# LAN9255ZMX020 register map
Vendor: Microchip
Registers are 32-bit, read-write, reset 0x0 unless marked. A register's access mark holds for its fields unless they carry their own. Addresses are absolute, and some are shared; only a register's first bit layout is shown; [hi:lo] are bit positions; {n}, {i} and the like mark numbered series; 'fields as' and 'values as' point back to an identical list.

## PAC
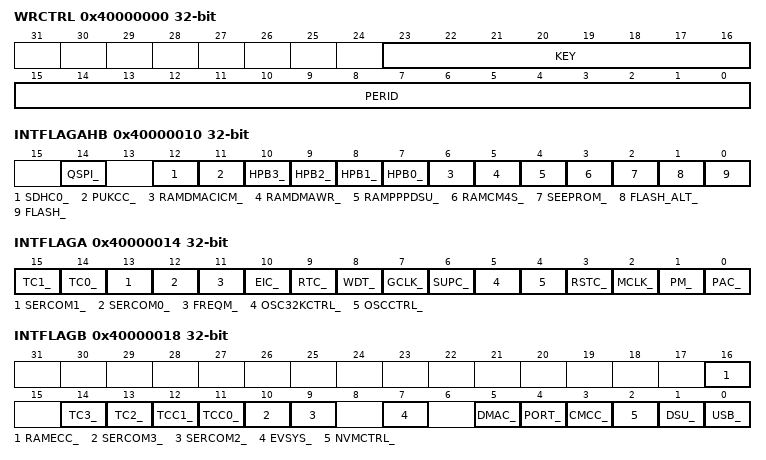
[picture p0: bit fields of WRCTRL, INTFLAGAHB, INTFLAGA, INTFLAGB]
0x40000000 WRCTRL
  [23:16] KEY — Peripheral access control key
    0=OFF (No action); 1=CLR (Clear protection); 2=SET (Set protection); 3=SETLCK (Set and lock protection)
  [15:0] PERID — Peripheral identifier
0x40000004 EVCTRL 8-bit
  [0] ERREO — Peripheral acess error event output
0x40000008 INTENCLR 8-bit
  [0] ERR — Peripheral access error interrupt disable
0x40000009 INTENSET 8-bit
  [0] ERR — Peripheral access error interrupt enable
0x40000010 INTFLAGAHB
  [14] QSPI_, [12] SDHC0_, [11] PUKCC_, [n+7] HPB{n}_ (n=0..3), [6] RAMDMACICM_, [5] RAMDMAWR_, [4] RAMPPPDSU_, [3] RAMCM4S_, [2] SEEPROM_, [1] FLASH_ALT_, [0] FLASH_
0x40000014 INTFLAGA
  [15] TC1_, [14] TC0_, [13] SERCOM1_, [12] SERCOM0_, [11] FREQM_, [10] EIC_, [9] RTC_, [8] WDT_, [7] GCLK_, [6] SUPC_, [5] OSC32KCTRL_, [4] OSCCTRL_, [3] RSTC_, [2] MCLK_, [1] PM_, [0] PAC_
0x40000018 INTFLAGB
  [16] RAMECC_, [14] TC3_, [13] TC2_, [12] TCC1_, [11] TCC0_, [10] SERCOM3_, [9] SERCOM2_, [7] EVSYS_, [5] DMAC_, [4] PORT_, [3] CMCC_, [2] NVMCTRL_, [1] DSU_, [0] USB_
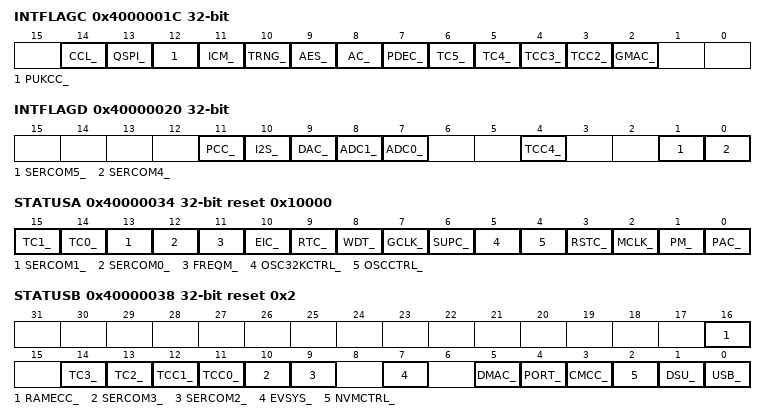
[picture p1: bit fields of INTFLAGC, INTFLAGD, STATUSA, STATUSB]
0x4000001C INTFLAGC
  [14] CCL_, [13] QSPI_, [12] PUKCC_, [11] ICM_, [10] TRNG_, [9] AES_, [8] AC_, [7] PDEC_, [6] TC5_, [5] TC4_, [4] TCC3_, [3] TCC2_, [2] GMAC_
0x40000020 INTFLAGD
  [11] PCC_, [10] I2S_, [9] DAC_, [8] ADC1_, [7] ADC0_, [4] TCC4_, [1] SERCOM5_, [0] SERCOM4_
0x40000034 STATUSA ro reset 0x10000
  [15] TC1_ — TC1 APB Protect Enable
  [14] TC0_ — TC0 APB Protect Enable
  [13] SERCOM1_ — SERCOM1 APB Protect Enable
  [12] SERCOM0_ — SERCOM0 APB Protect Enable
  [11] FREQM_ — FREQM APB Protect Enable
  [10] EIC_ — EIC APB Protect Enable
  [9] RTC_ — RTC APB Protect Enable
  [8] WDT_ — WDT APB Protect Enable
  [7] GCLK_ — GCLK APB Protect Enable
  [6] SUPC_ — SUPC APB Protect Enable
  [5] OSC32KCTRL_ — OSC32KCTRL APB Protect Enable
  [4] OSCCTRL_ — OSCCTRL APB Protect Enable
  [3] RSTC_ — RSTC APB Protect Enable
  [2] MCLK_ — MCLK APB Protect Enable
  [1] PM_ — PM APB Protect Enable
  [0] PAC_ — PAC APB Protect Enable
0x40000038 STATUSB ro reset 0x2
  [16] RAMECC_ — RAMECC APB Protect Enable
  [14] TC3_ — TC3 APB Protect Enable
  [13] TC2_ — TC2 APB Protect Enable
  [12] TCC1_ — TCC1 APB Protect Enable
  [11] TCC0_ — TCC0 APB Protect Enable
  [10] SERCOM3_ — SERCOM3 APB Protect Enable
  [9] SERCOM2_ — SERCOM2 APB Protect Enable
  [7] EVSYS_ — EVSYS APB Protect Enable
  [5] DMAC_ — DMAC APB Protect Enable
  [4] PORT_ — PORT APB Protect Enable
  [3] CMCC_ — CMCC APB Protect Enable
  [2] NVMCTRL_ — NVMCTRL APB Protect Enable
  [1] DSU_ — DSU APB Protect Enable
  [0] USB_ — USB APB Protect Enable
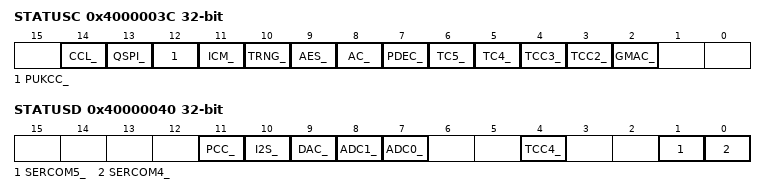
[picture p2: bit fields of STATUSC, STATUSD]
0x4000003C STATUSC ro
  [14] CCL_ — CCL APB Protect Enable
  [13] QSPI_ — QSPI APB Protect Enable
  [12] PUKCC_ — PUKCC APB Protect Enable
  [11] ICM_ — ICM APB Protect Enable
  [10] TRNG_ — TRNG APB Protect Enable
  [9] AES_ — AES APB Protect Enable
  [8] AC_ — AC APB Protect Enable
  [7] PDEC_ — PDEC APB Protect Enable
  [6] TC5_ — TC5 APB Protect Enable
  [5] TC4_ — TC4 APB Protect Enable
  [4] TCC3_ — TCC3 APB Protect Enable
  [3] TCC2_ — TCC2 APB Protect Enable
  [2] GMAC_ — GMAC APB Protect Enable
0x40000040 STATUSD ro
  [11] PCC_ — PCC APB Protect Enable
  [10] I2S_ — I2S APB Protect Enable
  [9] DAC_ — DAC APB Protect Enable
  [8] ADC1_ — ADC1 APB Protect Enable
  [7] ADC0_ — ADC0 APB Protect Enable
  [4] TCC4_ — TCC4 APB Protect Enable
  [1] SERCOM5_ — SERCOM5 APB Protect Enable
  [0] SERCOM4_ — SERCOM4 APB Protect Enable

## PM
0x40000400 CTRLA 8-bit
  [2] IORET — I/O Retention
0x40000401 SLEEPCFG 8-bit reset 0x2
  [2:0] SLEEPMODE
    2=IDLE (CPU, AHBx, and APBx clocks are OFF); 4=STANDBY (All Clocks are OFF); 5=HIBERNATE (Backup domain is ON as well as some PDRAMs); 6=BACKUP (Only Backup domain is powered ON); 7=OFF (All power domains are powered OFF)
0x40000404 INTENCLR 8-bit
  [0] SLEEPRDY — Sleep Mode Entry Ready Enable
0x40000405 INTENSET 8-bit
  [0] SLEEPRDY — Sleep Mode Entry Ready Enable
0x40000406 INTFLAG 8-bit
  [0] SLEEPRDY — Sleep Mode Entry Ready
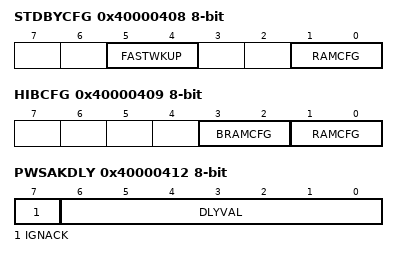
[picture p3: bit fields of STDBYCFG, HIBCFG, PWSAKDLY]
0x40000408 STDBYCFG 8-bit
  [5:4] FASTWKUP — Fast Wakeup
    0=NO (Fast Wakeup is disabled); 1=NVM (Fast Wakeup is enabled on NVM); 2=MAINVREG (Fast Wakeup is enabled on the main voltage regulator (MAINVREG)); 3=BOTH (Fast Wakeup is enabled on both NVM and MAINVREG)
  [1:0] RAMCFG — Ram Configuration
    0=RET (All the system RAM is retained); 1=PARTIAL (Only the first 32Kbytes of the system RAM is retained); 2=OFF (All the system RAM is turned OFF)
0x40000409 HIBCFG 8-bit
  [3:2] BRAMCFG — Backup Ram Configuration
    0=RET (All the backup RAM is retained); 1=PARTIAL (Only the first 4Kbytes of the backup RAM is retained); 2=OFF (All the backup RAM is turned OFF)
  [1:0] RAMCFG — Ram Configuration
    values as STDBYCFG.RAMCFG
0x4000040A BKUPCFG 8-bit
  [1:0] BRAMCFG — Ram Configuration
    values as HIBCFG.BRAMCFG
0x40000412 PWSAKDLY 8-bit
  [7] IGNACK — Ignore Acknowledge
  [6:0] DLYVAL — Delay Value
